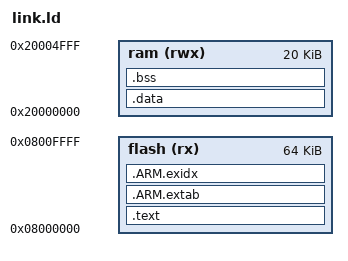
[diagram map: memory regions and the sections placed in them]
OUTPUT_FORMAT ("elf32-littlearm", "elf32-bigarm", "elf32-littlearm")

MEMORY {
    flash (rx ) : ORIGIN = 0x08000000, LENGTH = 64K
    ram   (rwx) : ORIGIN = 0x20000000, LENGTH = 20K
}

SECTIONS {
    .text : {
        KEEP(*(.isr_vector .isr_vector.*))
        *(.text .text.* .gnu.linkonce.t.*)
        *(.rodata .rodata* .gnu.linkonce.r.*)
        . = ALIGN(4);          
    } > flash

    .ARM.extab : {
        *(.ARM.extab* .gnu.linkonce.armextab.*)
    } > flash

    .ARM.exidx : {
        *(.ARM.exidx* .gnu.linkonce.armexidx.*)
    } > flash

    . = ALIGN(4);
    _etext = .;
    _sidata = .;

    .data : AT (_etext) {
        _sdata = .;
        *(.data .data.*)
        . = ALIGN(4);
        _edata = . ;
    } > ram

    .bss (NOLOAD) : {
        _sbss = . ;
        *(.bss .bss.*)
        *(COMMON)
        . = ALIGN(4);
        _ebss = . ;
    } > ram

    . = ALIGN(4);
    _end = . ;
}


